# ipro7 register map
Vendor: intelpro; Series: BTBLE
CPU: ipro7, little endian
Registers are 32-bit, read-write, reset 0x0 unless marked. A register's access mark holds for its fields unless they carry their own. Offsets are from the block's base; [hi:lo] are bit positions.

## HBN
Base 0x3008F000
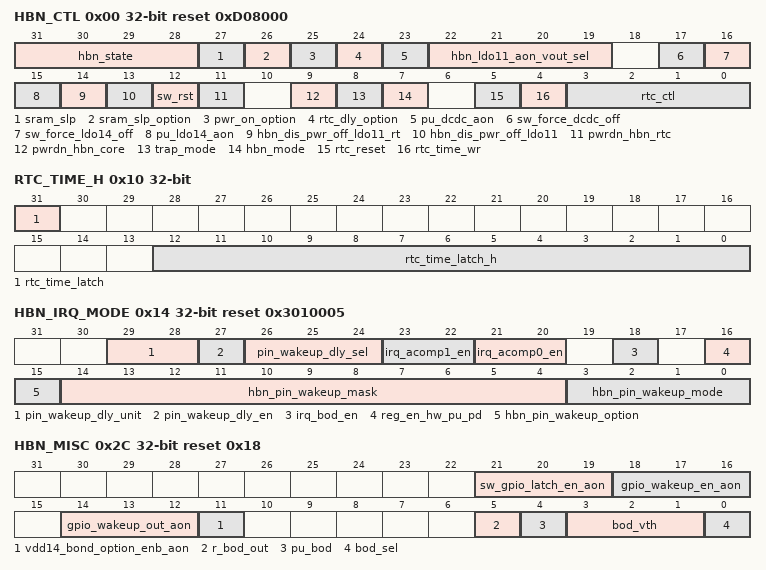
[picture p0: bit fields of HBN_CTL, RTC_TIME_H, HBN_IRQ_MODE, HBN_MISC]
0x00 HBN_CTL reset 0xD08000 (reset mask 0x7FFFEFF)
  [31:28] hbn_state ro — SW polling until 0 (default 4'h3 @pwron)
  [27] sram_slp ro — SW polling until 0 (default 1'b1 @pwron)
  [26] sram_slp_option
  [25] pwr_on_option
  [24] rtc_dly_option
  [23] pu_dcdc_aon — power up dcdc14 on power on seq
  [22:19] hbn_ldo11_aon_vout_sel — VDD11_AON Voltage Out Select @ Enter hibernate or PDS (control by cr_pds_ldo_vsel_en)
  [17] sw_force_dcdc_off — should only write this bit when hbn_rsvd2[11:0]=CDC
  [16] sw_force_ldo14_off — should only write this bit when hbn_rsvd2[11::0]=CDC
  [15] pu_ldo14_aon — power up ldo14 on power on seq
  [14] hbn_dis_pwr_off_ldo11_rt — Set 1 to disable power off VDDCORE_RT at HBN mode (for low power)
  [13] hbn_dis_pwr_off_ldo11 — Set 1 to disable power off VDDCORE at HBN mode (for debug)
  [12] sw_rst — soft reset
  [11] pwrdn_hbn_rtc — Power Off HBN RTC @ Enter hibernate
  [9] pwrdn_hbn_core — Power Off HBN Core @ Enter hibernate
  [8] trap_mode ro — Boot Strap 0: Flash, 1: UART or SDIO
  [7] hbn_mode wo — Enter hibernate
  [5] rtc_reset wo — RTC value reset
  [4] rtc_time_wr wo — RTC value writen by hbn_time (hbn_ctl[3]=1)
  [3:0] rtc_ctl — [6:4] Slow LED, x/0.25/0.5/1/2/4/8/16 seconds [3] rtc write mode [2] rtc short time 0~488s (bit 23~0 compare) [1] rtc time 0~353days*32 (bit 44~0 compare) [0] rtc enable
0x04 HBN_TIME_L
  [31:0] hbn_time_l — RTC timer compare bit 31:0 (rtc_ctl[3:1]=0 before change) RTC time write value bit 31:0 (if rtc_time_wr=1)
0x08 HBN_TIME_H
  [12:0] hbn_time_h — RTC timer compare bit 44:32 (rtc_ctl[3:1]=0 before change) RTC time write value bit 44:32 (if rtc_time_wr=1)
0x0C RTC_TIME_L reset not defined
  [31:0] rtc_time_latch_l ro — RTC time latched value bit 31:0
0x10 RTC_TIME_H (reset mask 0xFFFFE000)
  [31] rtc_time_latch wo — RTC time latch for SW read
  [12:0] rtc_time_latch_h ro — RTC time latched value bit 44:32
0x14 HBN_IRQ_MODE reset 0x3010005
  [29:28] pin_wakeup_dly_unit — Pin wakeup delay unit 0 : in unit of 250ms 1 :in unit of 31.25ms 2 : in unit of 1.953ms 3: in unit of 0.244ms
  [27] pin_wakeup_dly_en — Pin wakeup delay enable
  [26:24] pin_wakeup_dly_sel — the multiple number of Pin wakeup delay unit i.e. if Pin wakeup delay_unit = 250ms the delay range is 1~7 sec i.e. if Pin wakeup delay_unit = 0.244ms the delay range is 0.976ms~6.835ms
  [23:22] irq_acomp1_en — enable acomp1 interrupt [20] posedge [21] negedge
  [21:20] irq_acomp0_en — enable acomp0 interrupt [20] posedge [21] negedge
  [18] irq_bod_en — enable brown-out interrupt
  [16] reg_en_hw_pu_pd — 1: Pull GPIO30 @ pwr_on and pwr_rst : no pull
  [15] hbn_pin_wakeup_option — 1: Pin wakeup detect only at HBN 0 : No limited
  [14:4] hbn_pin_wakeup_mask — mask hbn_pin_wakeup_event (GPIO22/GPIO14/GPIO8/GPIO31/GPIO30/GPIO13~GPIO9)
  [3:0] hbn_pin_wakeup_mode — hbn_pin_wakeup mode 0000 : sync falling edge trigger 0001 : sync rising edge trigger 0010 : sync low level trigger 0011 : sync high level trigger 010x : sync rising or falling edge trigger 1000 : async falling edge trigger 1001 : async rising edge trigger 1010 : async low level trigger 1011 : async high level trigger
0x18 HBN_IRQ_STAT reset not defined
  [31:0] irq_stat ro — [22] acomp1 [20] acomp0 [18] brown-out [16] irq_rtc state [10:0] hbn_pin_wakeup state (GPIO7~14)
0x1C HBN_IRQ_CLR
  [31:0] irq_clr wo — [22] irq_acomp1 clear [20] irq_acomp0 clear [18] irq_bod clear [16] irq_rtc clear [10:0] hbn_pin_wakeup clear (GPIO7~14)
0x20 HBN_PIR_CFG
0x24 HBN_PIR_VTH
0x28 HBN_PIR_INTERVAL
0x2C HBN_MISC reset 0x18 (reset mask 0xFFFF8FDF)
  [21:19] sw_gpio_latch_en_aon — SW Keep GPIO [0] : GPIO0/1/2/3/7/8 [1] : GPIO14~20 [2] : GPIO21~29
  [18:16] gpio_wakeup_en_aon — GPIO Wakeup Enable for HBN (HW Try) [0] : GPIO8 [1]: GPIO14 [2] : GPIO22
  [14:12] gpio_wakeup_out_aon ro — GPIO Wakeup Enable for HBN (HW Try) [0] : GPIO8 [1]: GPIO14 [2] : GPIO22
  [11] vdd14_bond_option_enb_aon — bond option enable_b
  [5] r_bod_out ro
  [4] pu_bod — Power up Brown Out Detector
  [3:1] bod_vth — BOD threshold 0: 1.80V, 1: 1.85V, 2: 1.90V, 3: 1.95V 4: 2.00V, 5: 2.05V, 6: 2.10V, 7: 2.15V;
  [0] bod_sel — 0: POR is independent of BOD, 1: POR is relevant to BOD
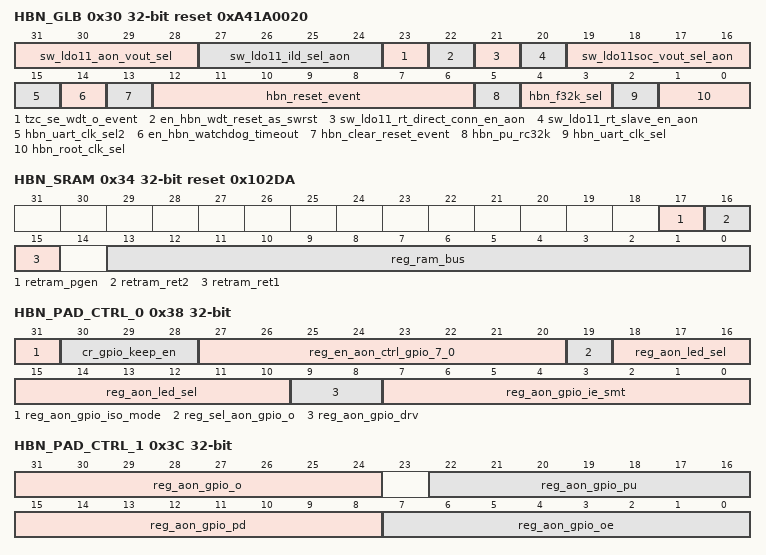
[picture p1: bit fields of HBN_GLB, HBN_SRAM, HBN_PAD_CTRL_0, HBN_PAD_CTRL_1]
0x30 HBN_GLB reset 0xA41A0020 (reset mask 0xFF7FE03F)
  [31:28] sw_ldo11_aon_vout_sel — aon ldo output voltage external control: 0:0.60V, 1:0.65V, 2:0.70V, 3:0.75V, 4:0.80V, 5:0.85V, 6:0.9V, 7:0.95V 8:1.0V, 9:1.05V, 10:1.1V, 11:1.15V, 12:1.2V, 13:1.25V, 14:1.3V, 15:1.35V
  [27:24] sw_ldo11_ild_sel_aon
  [23] tzc_se_wdt_o_event ro
  [22] en_hbn_wdt_reset_as_swrst
  [21] sw_ldo11_rt_direct_conn_en_aon
  [20] sw_ldo11_rt_slave_en_aon
  [19:16] sw_ldo11soc_vout_sel_aon — vdd11soc output voltage selection
  [15] hbn_uart_clk_sel2 — UART clock selection2 from HBN (0 : result of hbn_uart_clk_sel (fclk or dll_div2(64MHz)) 1: XCLK (XTAL or RC32M))
  [14] en_hbn_watchdog_timeout
  [13] hbn_clear_reset_event — clear reset event
  [12:6] hbn_reset_event ro — Reset/Timeout Event [6] : ldo11soc_timeout event [5] : dcdc_timeout event [4] : hbn_watchdog_timeout event [3] : bor_out_ event [2] : pwr_rst_n event [1] : sw_rst event [0] : por_out event
  [5] hbn_pu_rc32k — 0: Turn off rc32k during rtc power domain off, 1: Don't turn off rc32k
  [4:3] hbn_f32k_sel — 32KHz clock source selection (0: RC32K 1: XTAL 32K 3: DIG 32K)
  [2] hbn_uart_clk_sel — UART clock selection from HBN (0:fclk 1:dll_div2(64MHz))
  [1:0] hbn_root_clk_sel — root clock source selection (0: RC32M 1: XTAL 2/3: DLL)
0x34 HBN_SRAM reset 0x102DA
  [17] retram_pgen — make HBN RAM Sleep
  [16] retram_ret2 — make HBN RAM Retention
  [15] retram_ret1 — make HBN RAM Nap
  [13:0] reg_ram_bus — [13:12]=ram_bus[22:21]=WABLM_RF [11:10]=ram_bus[20:19]=RAWLM [9]=ram_bus[18]=WABL [8]=ram_bus[17]=RAWL [7:6]=ram_bus[16:15]=EMAW [5:3]=ram_bus[14:12]=EMA_RF [2:0]=ram_bus[11:9]=EMA_ROM
0x38 HBN_PAD_CTRL_0
  [31] reg_aon_gpio_iso_mode — 1: HW Keep GPIO @ PDS or HBN Mode 0 : No Keep GPIO @ PDS or HBN Mode
  [30:28] cr_gpio_keep_en — if reg_aon_gpio_iso_mode=1, can use bit to enable or disable IO latch function at enter HBN Mode [0] : GPIO0/1/2/3/7/8 [1] : GPIO14~20 [2] : GPIO21~29
  [27:20] reg_en_aon_ctrl_gpio_7_0 — AON GPIO10~17 Control by AON HW :
  [19] reg_sel_aon_gpio_o — AON PAD Output Selection : 1: Select reg_aon_pad 0 : Select aon led out
  [18:10] reg_aon_led_sel — (if corresponding AON GPIO controlled by AON HW) Always on PAD Output Slow LED, x/0.25/0.5/1/2/4/8/16 seconds [12:10] (for GPIO9/12/31) : reg_aon_led1_sel [15:13] (for GPIO10/13) : reg_aon_led2_sel [18:16] (for GPIO11/30) : reg_aon_led3_sel 1 : 0.25sec 2 : 0.5sec 3: 1 sec 4: 2sec 5: 4 sec 6 : 8sec 7 :16sec
  [9:8] reg_aon_gpio_drv — AON GPIO Driving Control
  [7:0] reg_aon_gpio_ie_smt — Always on PAD IE/SMT (if corresponding AON GPIO controlled by AON HW) GPIO10~17
0x3C HBN_PAD_CTRL_1
  [31:24] reg_aon_gpio_o — Always on PAD Output Value (if corresponding AON GPIO controlled by AON HW) GPIO10~17
  [22:16] reg_aon_gpio_pu — Always on PAD PU (if corresponding AON GPIO controlled by AON HW) GPIO10~17
  [15:8] reg_aon_gpio_pd — Always on PAD PD (if corresponding AON GPIO controlled by AON HW) GPIO10~17
  [7:0] reg_aon_gpio_oe — Always on PAD OE (if corresponding AON GPIO controlled by AON HW) GPIO10~17
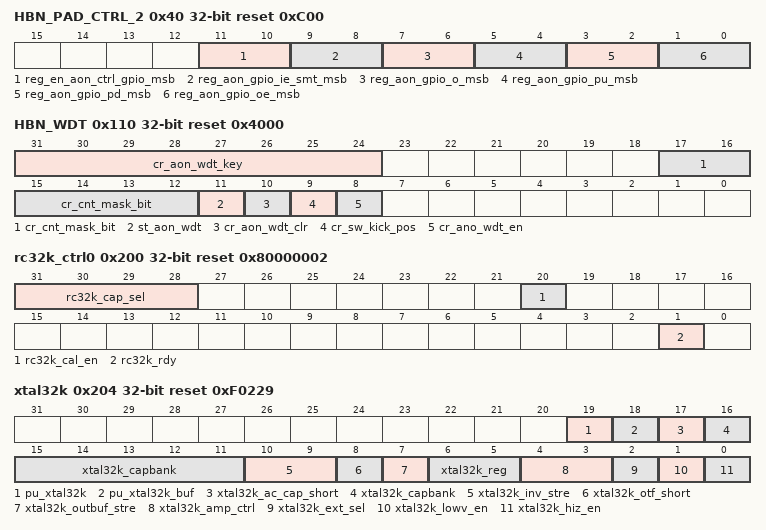
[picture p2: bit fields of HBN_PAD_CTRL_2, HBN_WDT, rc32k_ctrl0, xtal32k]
0x40 HBN_PAD_CTRL_2 reset 0xC00
  [11:10] reg_en_aon_ctrl_gpio_msb — AON GPIO18~19 Control by AON HW : [9] :GPIO19 (Default 1 : default for XTAL32K) [8]: GPIO18 (Default 1 : default for XTAL32K)
  [9:8] reg_aon_gpio_ie_smt_msb — Always on PAD IE/SMT (if corresponding AON GPIO controlled by AON HW) GPIO18~19
  [7:6] reg_aon_gpio_o_msb — Always on PAD Output Value (if corresponding AON GPIO controlled by AON HW) GPIO18~19
  [5:4] reg_aon_gpio_pu_msb — Always on PAD PU (if corresponding AON GPIO controlled by AON HW) GPIO18~19
  [3:2] reg_aon_gpio_pd_msb — Always on PAD PD (if corresponding AON GPIO controlled by AON HW) GPIO18~19
  [1:0] reg_aon_gpio_oe_msb — Always on PAD OE (if corresponding AON GPIO controlled by AON HW) GPIO18~19
0x100 HBN_RSV0
  [31:0] HBN_RSV0 — SW use for wakeup flag
0x104 HBN_RSV1 reset 0xFFFFFFFF
0x108 HBN_RSV2
0x10C HBN_RSV3 reset 0xFFFFFFFF
0x110 HBN_WDT reset 0x4000 (reset mask 0xFFFFF7FF)
  [31:24] cr_aon_wdt_key wo — Aon watch dog timer key
  [17:12] cr_cnt_mask_bit — Aon watch dog timer mask bit
  [11] st_aon_wdt ro — Aon watch dog timer reset status
  [10] cr_aon_wdt_clr wo — Aon watch dog timer reset status clear
  [9] cr_sw_kick_pos wo — Aon watch dog timer sw kick
  [8] cr_ano_wdt_en — Aon watch dog timer enable
0x200 rc32k_ctrl0 reset 0x80000002 (reset mask 0xFFFFFFFD)
  [31:28] rc32k_cap_sel
  [20] rc32k_cal_en — Enable calibration of 32k oscillator
  [1] rc32k_rdy ro — Asserts high when 32k clock is ready upon pwrup
0x204 xtal32k reset 0xF0229
  [19] pu_xtal32k — power up signal for 32K crystal oscillator
  [18] pu_xtal32k_buf — 1: power up XTAL32k level shifter buffer
  [17] xtal32k_ac_cap_short
  [16:11] xtal32k_capbank — 32K crystal load cap control word (also copy from efuse)
  [10:9] xtal32k_inv_stre — 32K crystal inverter amplify strength
  [8] xtal32k_otf_short — 32K crystal over tone filter short
  [7] xtal32k_outbuf_stre — 32K crystal output buffer strength
  [6:5] xtal32k_reg — 32K crystal voltage regulator level
  [4:3] xtal32k_amp_ctrl — 32K crystal oscillation amplitude control
  [2] xtal32k_ext_sel — External 32K clock enable
  [1] xtal32k_lowv_en
  [0] xtal32k_hiz_en
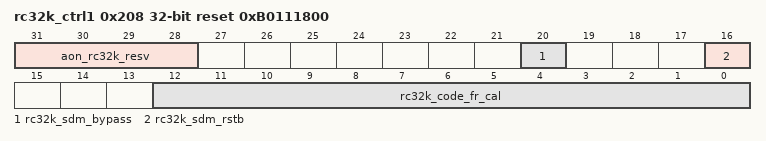
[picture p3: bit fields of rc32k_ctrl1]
0x208 rc32k_ctrl1 reset 0xB0111800
  [31:28] aon_rc32k_resv
  [20] rc32k_sdm_bypass
  [16] rc32k_sdm_rstb
  [12:0] rc32k_code_fr_cal — rc32k res code, can be refreshed after calibration. 10bit +3bit sdm
